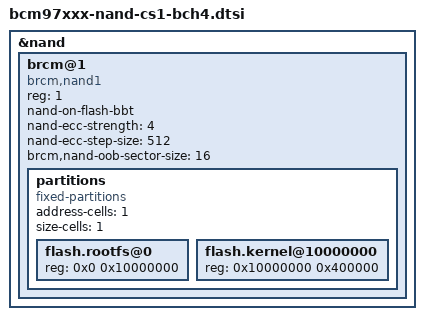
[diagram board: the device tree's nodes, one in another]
/*SPDX-License-Identifier: GPL-2.0 */

&nand {
	brcm@1 {
	compatible = "brcm,nand1";
	reg = <1>;
	nand-on-flash-bbt;

	nand-ecc-strength = <4>;
	nand-ecc-step-size = <512>;
	brcm,nand-oob-sector-size = <16>;

	partitions {
	compatible = "fixed-partitions";
	address-cells = <1>;
	size-cells = <1>;

	flash.rootfs@0 {
	reg = <0x0 0x10000000>;
	};

	flash.kernel@10000000 {
	reg = <0x10000000 0x400000>;
			};
		};
	};
};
